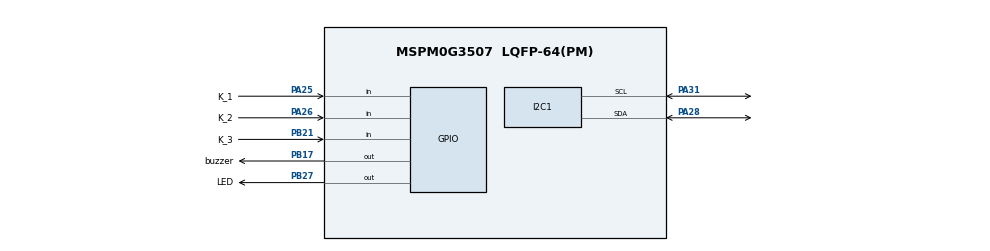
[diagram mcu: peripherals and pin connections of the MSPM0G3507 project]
/**
 * These arguments were used when this file was generated. They will be automatically applied on subsequent loads
 * via the GUI or CLI. Run CLI with '--help' for additional information on how to override these arguments.
 * @cliArgs --device "MSPM0G350X" --part "Default" --package "LQFP-64(PM)" --product "mspm0_sdk@2.11.00.07"
 * @v2CliArgs --device "MSPM0G3507" --package "LQFP-64(PM)" --product "mspm0_sdk@2.11.00.07"
 * @versions {"tool":"1.26.2+4477"}
 */

/**
 * Import the modules used in this configuration.
 */
const GPIO    = scripting.addModule("/ti/driverlib/GPIO", {}, false);
const GPIO1   = GPIO.addInstance();
const GPIO2   = GPIO.addInstance();
const GPIO3   = GPIO.addInstance();
const I2C     = scripting.addModule("/ti/driverlib/I2C", {}, false);
const I2C1    = I2C.addInstance();
const SYSCTL  = scripting.addModule("/ti/driverlib/SYSCTL");
const SYSTICK = scripting.addModule("/ti/driverlib/SYSTICK");

/**
 * Write custom configuration values to the imported modules.
 */
const divider9       = system.clockTree["UDIV"];
divider9.divideValue = 2;

const multiplier2         = system.clockTree["PLL_QDIV"];
multiplier2.multiplyValue = 5;

const mux8       = system.clockTree["HSCLKMUX"];
mux8.inputSelect = "HSCLKMUX_SYSPLL0";

GPIO1.$name                          = "LIGHT";
GPIO1.associatedPins[0].$name        = "LED";
GPIO1.associatedPins[0].initialValue = "SET";
GPIO1.associatedPins[0].pin.$assign  = "PB27";

const Board = scripting.addModule("/ti/driverlib/Board", {}, false);

GPIO2.$name                         = "BUZZER";
GPIO2.associatedPins[0].$name       = "buzzer";
GPIO2.associatedPins[0].pin.$assign = "PB17";

GPIO3.$name                              = "KEY";
GPIO3.associatedPins.create(3);
GPIO3.associatedPins[0].$name            = "K_1";
GPIO3.associatedPins[0].direction        = "INPUT";
GPIO3.associatedPins[0].interruptEn      = true;
GPIO3.associatedPins[0].polarity         = "FALL";
GPIO3.associatedPins[0].internalResistor = "PULL_UP";
GPIO3.associatedPins[0].pin.$assign      = "PA25";
GPIO3.associatedPins[1].$name            = "K_2";
GPIO3.associatedPins[1].direction        = "INPUT";
GPIO3.associatedPins[1].interruptEn      = true;
GPIO3.associatedPins[1].polarity         = "FALL";
GPIO3.associatedPins[1].internalResistor = "PULL_UP";
GPIO3.associatedPins[1].pin.$assign      = "PA26";
GPIO3.associatedPins[2].$name            = "K_3";
GPIO3.associatedPins[2].direction        = "INPUT";
GPIO3.associatedPins[2].internalResistor = "PULL_UP";
GPIO3.associatedPins[2].interruptEn      = true;
GPIO3.associatedPins[2].polarity         = "FALL";
GPIO3.associatedPins[2].pin.$assign      = "PB21";

I2C1.$name                             = "I2C_OLED";
I2C1.basicEnableController             = true;
I2C1.basicControllerStandardBusSpeed   = "Fast";
I2C1.peripheral.$assign                = "I2C0";
I2C1.peripheral.sdaPin.$assign         = "PA28";
I2C1.peripheral.sclPin.$assign         = "PA31";
I2C1.sdaPinConfig.$name                = "ti_driverlib_gpio_GPIOPinGeneric0";
I2C1.sdaPinConfig.hideOutputInversion  = scripting.forceWrite(false);
I2C1.sdaPinConfig.onlyInternalResistor = scripting.forceWrite(false);
I2C1.sdaPinConfig.passedPeripheralType = scripting.forceWrite("Digital");
I2C1.sclPinConfig.$name                = "ti_driverlib_gpio_GPIOPinGeneric1";
I2C1.sclPinConfig.hideOutputInversion  = scripting.forceWrite(false);
I2C1.sclPinConfig.onlyInternalResistor = scripting.forceWrite(false);
I2C1.sclPinConfig.passedPeripheralType = scripting.forceWrite("Digital");

SYSCTL.forceDefaultClkConfig = true;
SYSCTL.clockTreeEn           = true;

SYSTICK.periodEnable      = true;
SYSTICK.interruptEnable   = true;
SYSTICK.interruptPriority = "0";
SYSTICK.systickEnable     = true;
SYSTICK.period            = 80000;

/**
 * Pinmux solution for unlocked pins/peripherals. This ensures that minor changes to the automatic solver in a future
 * version of the tool will not impact the pinmux you originally saw.  These lines can be completely deleted in order to
 * re-solve from scratch.
 */
Board.peripheral.$suggestSolution          = "DEBUGSS";
Board.peripheral.swclkPin.$suggestSolution = "PA20";
Board.peripheral.swdioPin.$suggestSolution = "PA19";
